# ESP32-C6-LP register map
Vendor: ESPRESSIF SYSTEMS (SHANGHAI) CO., LTD.; Series: ESP32 C-Series; File version: 3
CPU: RV32IMAC r0p0, little endian, no MPU, no FPU, 0 interrupt priority bits
Address unit: 32 bits
Registers are 32-bit, read-write, reset 0x0 unless marked. A register's access mark holds for its fields unless they carry their own. Offsets are from the block's base; [hi:lo] are bit positions; lines under a group give offsets from that group; {n}, {i} and the like mark numbered series.

## LP_AON — LP_AON Peripheral
Base 0x600B1000
{0x0+4i} STORE{i} (i=0..9) — need_des
  [31:0] LP_AON_STORE{i}
0x28 GPIO_MUX — need_des
  [7:0] SEL
0x2C GPIO_HOLD0 — need_des
0x30 GPIO_HOLD1 — need_des
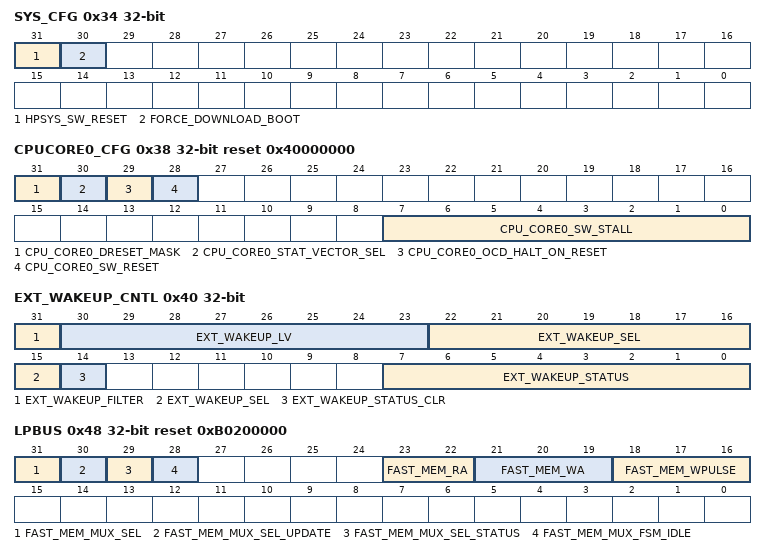
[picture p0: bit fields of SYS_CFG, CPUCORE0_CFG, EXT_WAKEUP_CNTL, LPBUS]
0x34 SYS_CFG access per field — need_des
  [31] HPSYS_SW_RESET wo — need_des
  [30] FORCE_DOWNLOAD_BOOT rw — need_des
0x38 CPUCORE0_CFG access per field reset 0x40000000 — need_des
  [31] CPU_CORE0_DRESET_MASK rw — need_des
  [30] CPU_CORE0_STAT_VECTOR_SEL rw — need_des
  [29] CPU_CORE0_OCD_HALT_ON_RESET rw — need_des
  [28] CPU_CORE0_SW_RESET wo — need_des
  [7:0] CPU_CORE0_SW_STALL rw — need_des
0x3C IO_MUX — need_des
  [31] RESET_DISABLE
0x40 EXT_WAKEUP_CNTL access per field — need_des
  [31] EXT_WAKEUP_FILTER rw — need_des
  [30:23] EXT_WAKEUP_LV rw — need_des
  [22:15] EXT_WAKEUP_SEL rw — need_des
  [14] EXT_WAKEUP_STATUS_CLR wo — need_des
  [7:0] EXT_WAKEUP_STATUS ro — need_des
0x44 USB — need_des
  [31] RESET_DISABLE
0x48 LPBUS access per field reset 0xB0200000 — need_des
  [31] FAST_MEM_MUX_SEL rw — need_des
  [30] FAST_MEM_MUX_SEL_UPDATE wo — need_des
  [29] FAST_MEM_MUX_SEL_STATUS ro — need_des
  [28] FAST_MEM_MUX_FSM_IDLE ro — need_des
  [23:22] FAST_MEM_RA rw — This field controls fast memory RA parameter.
  [21:19] FAST_MEM_WA rw — This field controls fast memory WA parameter.
  [18:16] FAST_MEM_WPULSE rw — This field controls fast memory WPULSE parameter.
0x4C SDIO_ACTIVE reset 0x2800000 — need_des
  [31:22] SDIO_ACT_DNUM
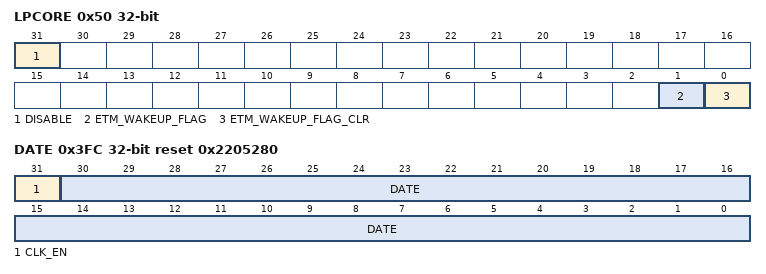
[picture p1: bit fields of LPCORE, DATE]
0x50 LPCORE access per field — need_des
  [31] DISABLE rw — need_des
  [1] ETM_WAKEUP_FLAG rw — need_des
  [0] ETM_WAKEUP_FLAG_CLR wo — need_des
0x54 SAR_CCT — need_des
  [31:29] SAR2_PWDET_CCT
0x3FC DATE reset 0x2205280 — need_des
  [31] CLK_EN — need_des
  [30:0] DATE — need_des

## LP_APM — Low-power Access Permission Management Controller
Base 0x600B3800
0x00 REGION_FILTER_EN reset 0x1 — Region filter enable register
  [3:0] REGION_FILTER_EN — Region filter enable
{0x4+0xC*i} REGION{i} (i=0..3) group — Cluster REGION{i}, containing REGION*_ADDR_START, REGION*_ADDR_END, REGION*_PMS_ATTR
  0x00 ADDR_START — Region address register
    [31:0] ADDR_START — Start address of region0
  0x04 ADDR_END reset 0xFFFFFFFF — Region address register
    [31:0] ADDR_END — End address of region0
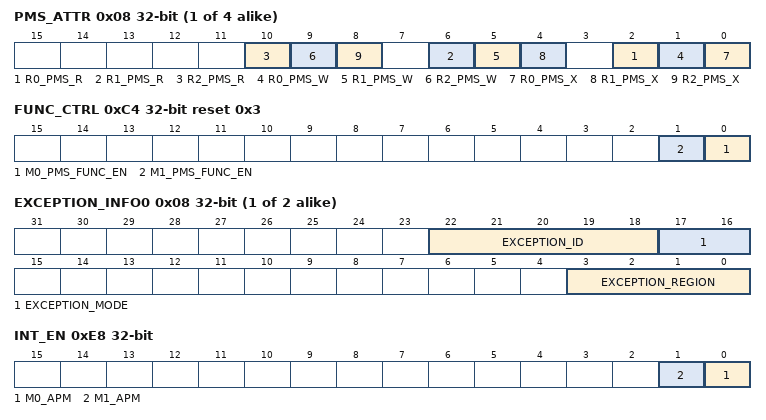
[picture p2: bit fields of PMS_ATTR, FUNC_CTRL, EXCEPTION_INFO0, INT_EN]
  0x08 PMS_ATTR — Region access authority attribute register
    [4n+2] R{n}_PMS_R (n=0..2) — Region read authority in REE_MODE{n}
    [4n+1] R{n}_PMS_W (n=0..2) — Region write authority in REE_MODE{n}
    [4n] R{n}_PMS_X (n=0..2) — Region execute authority in REE_MODE{n}
0xC4 FUNC_CTRL reset 0x3 — PMS function control register
  [n] M{n}_PMS_FUNC_EN (n=0..1) — PMS M{n} function enable
{0xC8+0x10*i} M{i} (i=0..1) group — Cluster M{i}, containing M?_STATUS, M?_STATUS_CLR, M?_EXCEPTION_INFO0, M?_EXCEPTION_INFO1
  0x00 STATUS ro — M0 status register
    [1:0] EXCEPTION_STATUS
  0x04 STATUS_CLR wo — M0 status clear register
    [0] REGION_STATUS_CLR — Clear exception status
  0x08 EXCEPTION_INFO0 ro — M0 exception_info0 register
    [22:18] EXCEPTION_ID — Exception id information
    [17:16] EXCEPTION_MODE
    [3:0] EXCEPTION_REGION
  0x0C EXCEPTION_INFO1 ro — M0 exception_info1 register
    [31:0] EXCEPTION_ADDR
0xE8 INT_EN — APM interrupt enable register
  [n] M{n}_APM (n=0..1) — APM M{n} interrupt enable
0xEC CLOCK_GATE reset 0x1 — clock gating register
  [0] CLK_EN — reg_clk_en
0xFC DATE reset 0x2205240 — Version register
  [27:0] DATE — reg_date

## LP_CLKRST — LP_CLKRST Peripheral
Base 0x600B0400
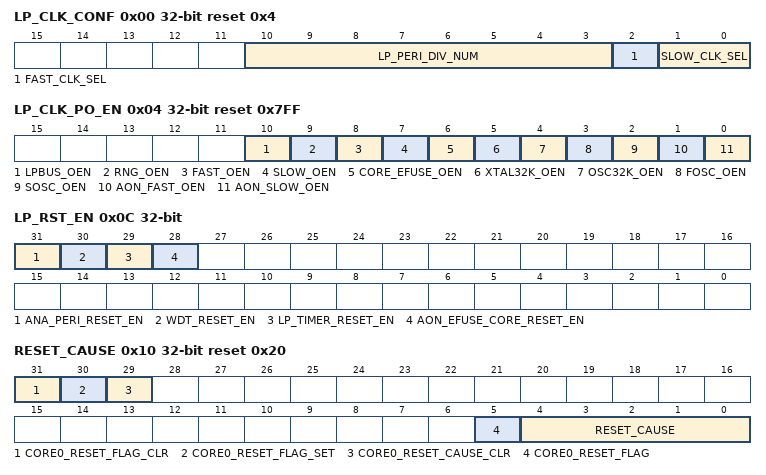
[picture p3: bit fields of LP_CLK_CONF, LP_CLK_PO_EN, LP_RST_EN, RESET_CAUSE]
0x00 LP_CLK_CONF reset 0x4 — need_des
  [10:3] LP_PERI_DIV_NUM — need_des
  [2] FAST_CLK_SEL — need_des
  [1:0] SLOW_CLK_SEL — need_des
0x04 LP_CLK_PO_EN reset 0x7FF — need_des
  [10] LPBUS_OEN — need_des
  [9] RNG_OEN — need_des
  [8] FAST_OEN — need_des
  [7] SLOW_OEN — need_des
  [6] CORE_EFUSE_OEN — need_des
  [5] XTAL32K_OEN — need_des
  [4] OSC32K_OEN — need_des
  [3] FOSC_OEN — need_des
  [2] SOSC_OEN — need_des
  [1] AON_FAST_OEN — need_des
  [0] AON_SLOW_OEN — need_des
0x08 LP_CLK_EN — need_des
  [31] FAST_ORI_GATE
0x0C LP_RST_EN — need_des
  [31] ANA_PERI_RESET_EN — need_des
  [30] WDT_RESET_EN — need_des
  [29] LP_TIMER_RESET_EN — need_des
  [28] AON_EFUSE_CORE_RESET_EN — need_des
0x10 RESET_CAUSE access per field reset 0x20 — need_des
  [31] CORE0_RESET_FLAG_CLR wo — need_des
  [30] CORE0_RESET_FLAG_SET wo — need_des
  [29] CORE0_RESET_CAUSE_CLR wo — need_des
  [5] CORE0_RESET_FLAG ro — need_des
  [4:0] RESET_CAUSE ro — need_des
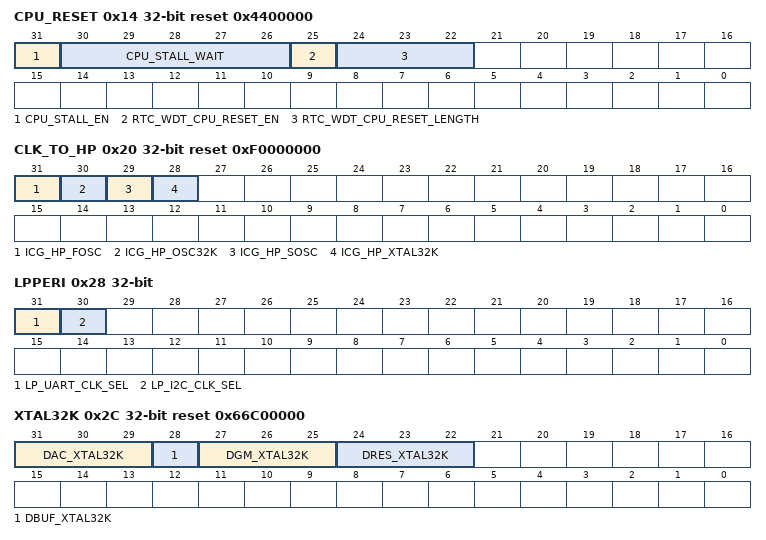
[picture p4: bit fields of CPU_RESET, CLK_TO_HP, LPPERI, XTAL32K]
0x14 CPU_RESET reset 0x4400000 — need_des
  [31] CPU_STALL_EN — need_des
  [30:26] CPU_STALL_WAIT — need_des
  [25] RTC_WDT_CPU_RESET_EN — need_des
  [24:22] RTC_WDT_CPU_RESET_LENGTH — need_des
0x18 FOSC_CNTL reset 0x2B000000 — need_des
  [31:22] FOSC_DFREQ
0x1C RC32K_CNTL reset 0x2B000000 — need_des
  [31:22] RC32K_DFREQ
0x20 CLK_TO_HP reset 0xF0000000 — need_des
  [31] ICG_HP_FOSC — need_des
  [30] ICG_HP_OSC32K — need_des
  [29] ICG_HP_SOSC — need_des
  [28] ICG_HP_XTAL32K — need_des
0x24 LPMEM_FORCE — need_des
  [31] LPMEM_CLK_FORCE_ON
0x28 LPPERI — need_des
  [31] LP_UART_CLK_SEL — need_des
  [30] LP_I2C_CLK_SEL — need_des
0x2C XTAL32K reset 0x66C00000 — need_des
  [31:29] DAC_XTAL32K — need_des
  [28] DBUF_XTAL32K — need_des
  [27:25] DGM_XTAL32K — need_des
  [24:22] DRES_XTAL32K — need_des
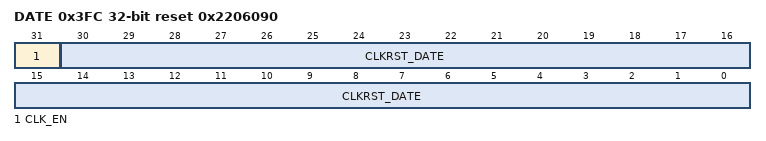
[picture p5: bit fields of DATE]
0x3FC DATE reset 0x2206090 — need_des
  [31] CLK_EN — need_des
  [30:0] CLKRST_DATE — need_des

## Notices in the file
Copyright 2025 Espressif Systems (Shanghai) PTE LTD
Licensed under the Apache License, Version 2.0 (the "License");
you may not use this file except in compliance with the License.
You may obtain a copy of the License at
http://www.apache.org/licenses/LICENSE-2.0
Unless required by applicable law or agreed to in writing, software
distributed under the License is distributed on an "AS IS" BASIS,
WITHOUT WARRANTIES OR CONDITIONS OF ANY KIND, either express or implied.
See the License for the specific language governing permissions and
limitations under the License.
